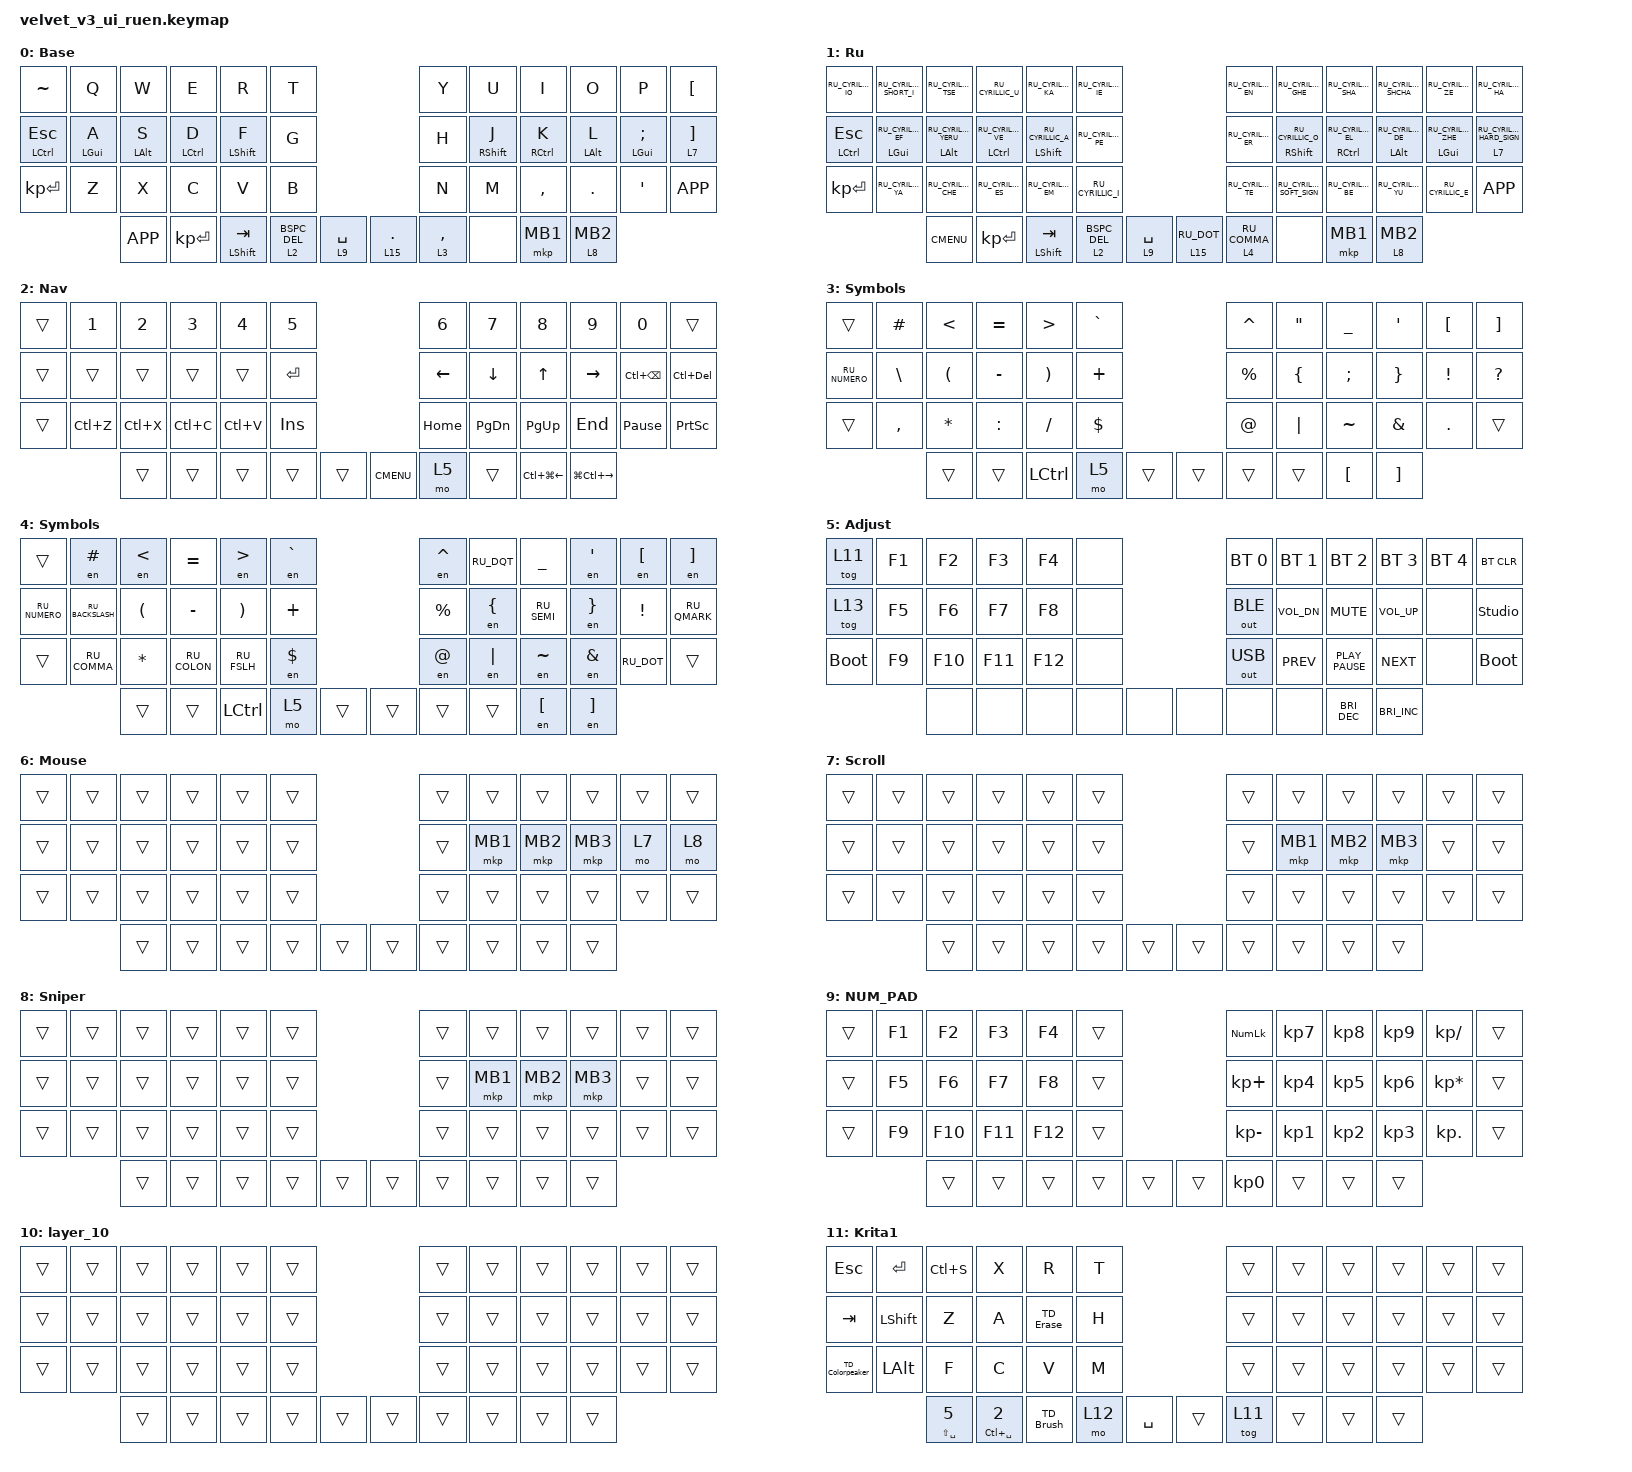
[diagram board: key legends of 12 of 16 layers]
#include "keys_ru.h"
#include <dt-bindings/zmk/input_transform.h>
#include <input/processors.dtsi>
#include <zephyr/dt-bindings/input/input-event-codes.h>
#include <scroll-snap.dtsi>
#include <behaviors.dtsi>
#include <dt-bindings/zmk/bt.h>
#include <dt-bindings/zmk/keys.h>
#include <dt-bindings/zmk/outputs.h>
#include <dt-bindings/zmk/pointing.h>

/ {
    behaviors {
        cap_sen: cap_sen {
            compatible = "zmk,behavior-hold-tap";
            label = "CAP_SEN";
            bindings = <&mo>, <&mkp>;

            #binding-cells = <2>;
            tapping-term-ms = <150>;
            hold-while-undecided;
        };

        hrml: hrml {
            compatible = "zmk,behavior-hold-tap";
            label = "HRML";
            bindings = <&kp>, <&kp>;

            #binding-cells = <2>;
            tapping-term-ms = <175>;
            quick-tap-ms = <175>;
            require-prior-idle-ms = <100>;
            flavor = "balanced";
            hold-trigger-on-release;
            hold-trigger-key-positions = <6 7 8 9 10 11 18 19 20 21 22 23 30 31 32 33 34 35 42 43 44 45 41>;
        };

        hrmr: hrmr {
            compatible = "zmk,behavior-hold-tap";
            label = "HRMR";
            bindings = <&kp>, <&kp>;

            #binding-cells = <2>;
            tapping-term-ms = <175>;
            quick-tap-ms = <175>;
            require-prior-idle-ms = <100>;
            flavor = "balanced";
            hold-trigger-on-release;
            hold-trigger-key-positions = <0 1 2 3 4 5 12 13 14 15 16 17 24 25 26 27 28 29 36 37 38 39 40>;
        };

        TD_Brush: TD_Brush {
            compatible = "zmk,behavior-tap-dance";
            label = "TD_BRUSH";
            #binding-cells = <0>;
            bindings = <&kp B>, <&kp Q>;
        };

        TD_Erase: TD_Erase {
            compatible = "zmk,behavior-tap-dance";
            label = "TD_ERASE";
            #binding-cells = <0>;
            bindings = <&kp E>, <&kp LA(E)>;
        };

        TD_Colorpeaker: TD_Colorpeaker {
            compatible = "zmk,behavior-tap-dance";
            label = "TD_COLORPEAKER";
            #binding-cells = <0>;
            bindings = <&kp LCTRL>, <&kp LA(LCTRL)>;
        };

        MBL_LT: MBL_LT {
            compatible = "zmk,behavior-hold-tap";
            label = "MBL_LT";
            bindings = <&mo>, <&mkp>;

            #binding-cells = <2>;
            hold-trigger-key-positions = <42>;
            tapping-term-ms = <175>;
            require-prior-idle-ms = <100>;
            quick-tap-ms = <150>;
            flavor = "balanced";
            hold-trigger-on-release;
        };

        BSPC_DEL: BSPC_DEL {
            compatible = "zmk,behavior-mod-morph";
            label = "BSPC_DEL";
            bindings = <&kp BSPC>, <&kp DEL>;

            #binding-cells = <0>;
            mods = <(MOD_LSFT|MOD_RSFT)>;
        };

        BCSP_DEL_NAV: BCSP_DEL_NAV {
            compatible = "zmk,behavior-hold-tap";
            label = "BCSP_DEL_NAV";
            bindings = <&mo>, <&BSPC_DEL>;

            #binding-cells = <2>;
            tapping-term-ms = <150>;
            hold-trigger-key-positions = <39>;
            quick-tap-ms = <125>;
            require-prior-idle-ms = <100>;
        };

        mouse_layer: mouse_layer {
            compatible = "zmk,behavior-sticky-key";
            label = "MOUSE_LAYER";
            bindings = <&mo>;
            #binding-cells = <1>;
            release-after-ms = <200>;
        };

        zip_auto_mouse: zip_auto_mouse {
            compatible = "zmk,input-processor-temp-layer";
            #input-processor-cells = <2>;
            require-prior-idle-ms = <800>;
            excluded-positions = <>;
        };
    };

    combos {
        compatible = "zmk,combos";

        cmben {
            bindings = <&layer_en>;
            key-positions = <3 4>;
            layers = <1>;
        };

        cmbru {
            bindings = <&layer_ru>;
            key-positions = <3 4>;
            layers = <0>;
        };

        rusync {
            bindings = <&to 0>;
            key-positions = <8 7>;
            layers = <1>;
        };

        ensycn {
            bindings = <&to 1>;
            key-positions = <8 7>;
            layers = <0>;
        };

        SemiEN {
            bindings = <&kp SEMI>;
            key-positions = <42 41>;
            layers = <0>;
        };

        SemiRU {
            bindings = <&kp RU_SEMI>;
            key-positions = <42 41>;
            layers = <1>;
        };

        MbScrolMode {
            bindings = <&MBL_LT 7 MCLK>;
            key-positions = <44 45>;
            layers = <0 1 2 3 4 5 6 7 8 9>;
        };
    };

    macros {
        to_ru: to_ru {
            compatible = "zmk,behavior-macro";
            #binding-cells = <0>;
            bindings = <&kp LG(SPACE)>;
            label = "TO_RU";
            wait-ms = <0>;
            tap-ms = <0>;
        };

        to_en: to_en {
            compatible = "zmk,behavior-macro";
            #binding-cells = <0>;
            bindings = <&kp LG(SPACE)>;
            label = "TO_EN";
            wait-ms = <0>;
            tap-ms = <0>;
        };

        layer_en: layer_en {
            compatible = "zmk,behavior-macro";
            #binding-cells = <0>;
            bindings = <&to 0 &to_en>;
            label = "LAYER_EN";
            wait-ms = <0>;
            tap-ms = <30>;
        };

        layer_ru: layer_ru {
            compatible = "zmk,behavior-macro";
            #binding-cells = <0>;
            bindings = <&to 1 &to_ru>;
            label = "LAYER_RU";
            tap-ms = <30>;
            wait-ms = <0>;
        };

        en: en {
            compatible = "zmk,behavior-macro-one-param";
            #binding-cells = <1>;
            bindings =
                <&to_en>,
                <&macro_press>,
                <&macro_param_1to1 &kp MACRO_PLACEHOLDER>,
                <&macro_pause_for_release>,
                <&macro_release>,
                <&macro_param_1to1 &kp MACRO_PLACEHOLDER>,
                <&macro_tap>,
                <&to_ru>;

            label = "EN";
            wait-ms = <0>;
            tap-ms = <30>;
        };
    };

    keymap {
        compatible = "zmk,keymap";

        en {
            bindings = <
&kp TILDE      &kp Q             &kp W             &kp E          &kp R               &kp T                                         &kp Y        &kp U                &kp I          &kp O             &kp P                &kp LEFT_BRACKET
&mt LCTRL ESC  &hrml LEFT_GUI A  &hrml LEFT_ALT S  &hrml LCTRL D  &hrml LEFT_SHIFT F  &kp G                                         &kp H        &hrmr RIGHT_SHIFT J  &hrmr RCTRL K  &hrmr LEFT_ALT L  &hrmr LEFT_GUI SEMI  &lt 7 RIGHT_BRACKET
&kp KP_ENTER   &kp Z             &kp X             &kp C          &kp V               &kp B                                         &kp N        &kp M                &kp COMMA      &kp DOT           &kp SQT              &kp K_APP
                                 &kp K_APP         &kp KP_ENTER   &mt LEFT_SHIFT TAB  &BCSP_DEL_NAV 2 0  &lt 9 SPACE    &lt 15 DOT  &lt 3 COMMA  &none                &mkp MB1       &MBL_LT 8 MB2
            >;

            display-name = "Base";
        };

        ru {
            display-name = "Ru";
            bindings = <
&kp RU_CYRILLIC_IO  &kp RU_CYRILLIC_SHORT_I        &kp RU_CYRILLIC_TSE              &kp RU_CYRILLIC_U           &kp RU_CYRILLIC_KA              &kp RU_CYRILLIC_IE                                &kp RU_CYRILLIC_EN  &kp RU_CYRILLIC_GHE         &kp RU_CYRILLIC_SHA         &kp RU_CYRILLIC_SHCHA          &kp RU_CYRILLIC_ZE          &kp RU_CYRILLIC_HA
&mt LCTRL ESC       &hrml LEFT_GUI RU_CYRILLIC_EF  &hrml LEFT_ALT RU_CYRILLIC_YERU  &hrml LCTRL RU_CYRILLIC_VE  &hrml LEFT_SHIFT RU_CYRILLIC_A  &kp RU_CYRILLIC_PE                                &kp RU_CYRILLIC_ER  &hrmr RSHIFT RU_CYRILLIC_O  &hrmr RCTRL RU_CYRILLIC_EL  &hrmr LEFT_ALT RU_CYRILLIC_DE  &hrmr LGUI RU_CYRILLIC_ZHE  &lt 7 RU_CYRILLIC_HARD_SIGN
&kp KP_ENTER        &kp RU_CYRILLIC_YA             &kp RU_CYRILLIC_CHE              &kp RU_CYRILLIC_ES          &kp RU_CYRILLIC_EM              &kp RU_CYRILLIC_I                                 &kp RU_CYRILLIC_TE  &kp RU_CYRILLIC_SOFT_SIGN   &kp RU_CYRILLIC_BE          &kp RU_CYRILLIC_YU             &kp RU_CYRILLIC_E           &kp K_APP
                                                   &kp K_CMENU                      &kp KP_ENTER                &mt LEFT_SHIFT TAB              &BCSP_DEL_NAV 2 0   &lt 9 SPACE    &lt 15 RU_DOT  &lt 4 RU_COMMA      &none                       &mkp MB1                    &MBL_LT 8 MB2
            >;
        };

        nav {
            bindings = <
&trans  &kp N1     &kp N2     &kp N3     &kp N4     &kp N5                          &kp NUMBER_6  &kp NUMBER_7   &kp NUMBER_8      &kp N9             &kp N0             &trans
&trans  &trans     &trans     &trans     &trans     &kp RET                         &kp LEFT      &kp DOWN       &kp UP            &kp RIGHT          &kp LC(BACKSPACE)  &kp LC(DEL)
&trans  &kp LC(Z)  &kp LC(X)  &kp LC(C)  &kp LC(V)  &kp INS                         &kp HOME      &kp PAGE_DOWN  &kp PG_UP         &kp END            &kp PAUSE_BREAK    &kp PRINTSCREEN
                   &trans     &trans     &trans     &trans   &trans    &kp K_CMENU  &mo 5         &trans         &kp LC(LG(LEFT))  &kp LG(LC(RIGHT))
            >;

            display-name = "Nav";
        };

        sym_en {
            bindings = <
&trans         &kp HASH   &kp LT    &kp EQUAL  &kp GT     &kp GRAVE                    &kp CARET  &kp DQT   &kp UNDER  &kp SQT   &kp LBKT  &kp RBKT
&kp RU_NUMERO  &kp BSLH   &kp LPAR  &kp MINUS  &kp RPAR   &kp PLUS                     &kp PRCNT  &kp LBRC  &kp SEMI   &kp RBRC  &kp EXCL  &kp QUESTION
&trans         &kp COMMA  &kp STAR  &kp COLON  &kp FSLH   &kp DLLR                     &kp AT     &kp PIPE  &kp TILDE  &kp AMPS  &kp DOT   &trans
                          &trans    &trans     &kp LCTRL  &mo 5      &trans    &trans  &trans     &trans    &kp LBKT   &kp RBKT
            >;

            display-name = "Symbols";
        };

        sym_ru {
            display-name = "Symbols";
            bindings = <
&trans         &en HASH          &en LT    &kp EQUAL     &en GT       &en GRAVE                    &en CARET  &kp RU_DQT  &kp UNDER    &en SQT   &en LBKT    &en RBKT
&kp RU_NUMERO  &kp RU_BACKSLASH  &kp LPAR  &kp MINUS     &kp RPAR     &kp PLUS                     &kp PRCNT  &en LBRC    &kp RU_SEMI  &en RBRC  &kp EXCL    &kp RU_QMARK
&trans         &kp RU_COMMA      &kp STAR  &kp RU_COLON  &kp RU_FSLH  &en DLLR                     &en AT     &en PIPE    &en TILDE    &en AMPS  &kp RU_DOT  &trans
                                 &trans    &trans        &kp LCTRL    &mo 5      &trans    &trans  &trans     &trans      &en LBKT     &en RBKT
            >;
        };

        adj {
            bindings = <
&tog 11      &kp F1  &kp F2   &kp F3   &kp F4   &none                  &bt BT_SEL 0  &bt BT_SEL 1  &bt BT_SEL 2          &bt BT_SEL 3          &bt BT_SEL 4  &bt BT_CLR
&tog 13      &kp F5  &kp F6   &kp F7   &kp F8   &none                  &out OUT_BLE  &kp C_VOL_DN  &kp K_MUTE            &kp C_VOL_UP          &none         &studio_unlock
&bootloader  &kp F9  &kp F10  &kp F11  &kp F12  &none                  &out OUT_USB  &kp K_PREV    &kp K_PLAY_PAUSE      &kp K_NEXT            &none         &bootloader
                     &none    &none    &none    &none  &none    &none  &none         &none         &kp C_BRIGHTNESS_DEC  &kp C_BRIGHTNESS_INC
            >;

            display-name = "Adjust";
        };

        mouse {
            bindings = <
&trans  &trans  &trans  &trans  &trans  &trans                    &trans  &trans    &trans    &trans    &trans  &trans
&trans  &trans  &trans  &trans  &trans  &trans                    &trans  &mkp MB1  &mkp MB2  &mkp MB3  &mo 7   &mo 8
&trans  &trans  &trans  &trans  &trans  &trans                    &trans  &trans    &trans    &trans    &trans  &trans
                &trans  &trans  &trans  &trans  &trans    &trans  &trans  &trans    &trans    &trans
            >;

            display-name = "Mouse";
        };

        scroll {
            bindings = <
&trans  &trans  &trans  &trans  &trans  &trans                    &trans  &trans    &trans    &trans    &trans  &trans
&trans  &trans  &trans  &trans  &trans  &trans                    &trans  &mkp MB1  &mkp MB2  &mkp MB3  &trans  &trans
&trans  &trans  &trans  &trans  &trans  &trans                    &trans  &trans    &trans    &trans    &trans  &trans
                &trans  &trans  &trans  &trans  &trans    &trans  &trans  &trans    &trans    &trans
            >;

            display-name = "Scroll";
        };

        sniper {
            bindings = <
&trans  &trans  &trans  &trans  &trans  &trans                    &trans  &trans    &trans    &trans    &trans  &trans
&trans  &trans  &trans  &trans  &trans  &trans                    &trans  &mkp MB1  &mkp MB2  &mkp MB3  &trans  &trans
&trans  &trans  &trans  &trans  &trans  &trans                    &trans  &trans    &trans    &trans    &trans  &trans
                &trans  &trans  &trans  &trans  &trans    &trans  &trans  &trans    &trans    &trans
            >;

            display-name = "Sniper";
        };

        NUM_PAD {
            bindings = <
&trans  &kp F1  &kp F2   &kp F3   &kp F4   &trans                    &kp KP_NUMLOCK   &kp KP_N7  &kp KP_N8  &kp KP_N9  &kp KP_SLASH     &trans
&trans  &kp F5  &kp F6   &kp F7   &kp F8   &trans                    &kp KP_PLUS      &kp KP_N4  &kp KP_N5  &kp KP_N6  &kp KP_MULTIPLY  &trans
&trans  &kp F9  &kp F10  &kp F11  &kp F12  &trans                    &kp KP_MINUS     &kp KP_N1  &kp KP_N2  &kp KP_N3  &kp KP_DOT       &trans
                &trans   &trans   &trans   &trans  &trans    &trans  &kp KP_NUMBER_0  &trans     &trans     &trans
            >;
        };

        layer_10 {
            bindings = <
&trans  &trans  &trans  &trans  &trans  &trans                    &trans  &trans  &trans  &trans  &trans  &trans
&trans  &trans  &trans  &trans  &trans  &trans                    &trans  &trans  &trans  &trans  &trans  &trans
&trans  &trans  &trans  &trans  &trans  &trans                    &trans  &trans  &trans  &trans  &trans  &trans
                &trans  &trans  &trans  &trans  &trans    &trans  &trans  &trans  &trans  &trans
            >;
        };

        Krita1 {
            bindings = <
&kp ESC          &kp RET    &kp LC(S)         &kp X                   &kp R      &kp T                        &trans   &trans  &trans  &trans  &trans  &trans
&kp TAB          &kp LSHFT  &kp Z             &kp A                   &TD_Erase  &kp H                        &trans   &trans  &trans  &trans  &trans  &trans
&TD_Colorpeaker  &kp LALT   &kp F             &kp C                   &kp V      &kp M                        &trans   &trans  &trans  &trans  &trans  &trans
                            &mt LS(SPACE) N5  &mt LC(SPACE) NUMBER_2  &TD_Brush  &mo 12  &kp SPACE    &trans  &tog 11  &trans  &trans  &trans
            >;
        };

        Krita2 {
            bindings = <
&trans         &kp LC(G)           &kp LC(E)   &kp LC(T)      &kp INS    &kp LC(INS)                    &trans  &trans  &trans  &trans  &trans  &trans
&kp LC(LS(I))  &kp LS(LC(A))       &kp LC(A)   &kp LC(PG_UP)  &kp LA(H)  &kp LA(INS)                    &trans  &trans  &trans  &trans  &trans  &trans
&trans         &kp LC(LS(DELETE))  &kp DELETE  &kp LC(PG_DN)  &kp LS(H)  &kp LC(N)                      &trans  &trans  &trans  &trans  &trans  &trans
                                   &kp LC(C)   &kp LC(V)      &trans     &trans       &trans    &trans  &trans  &trans  &trans  &trans
            >;
        };

        GameBase {
            bindings = <
&kp ESC    &kp GRAVE       &kp Q  &kp W  &kp E   &kp R                         &trans     &trans    &kp UP    &trans     &trans  &trans
&kp RCTRL  &kp LEFT_SHIFT  &kp A  &kp S  &kp D   &kp F                         &trans     &kp LEFT  &kp DOWN  &kp RIGHT  &trans  &trans
&kp LALT   &kp Z           &kp X  &kp C  &kp V   &kp B                         &trans     &trans    &trans    &trans     &trans  &trans
                           &kp I  &kp M  &trans  &kp SPACE  &mo 14    &tog 13  &kp SPACE  &trans    &trans    &trans
            >;
        };

        GameFunc {
            bindings = <
&trans  &kp N1  &kp N2   &kp N3   &kp N4  &kp N5                    &trans  &trans  &trans  &trans  &trans  &trans
&trans  &kp N6  &kp N7   &kp N8   &kp N9  &kp N0                    &trans  &trans  &trans  &trans  &trans  &trans
&trans  &kp G   &kp J    &kp I    &kp M   &kp T                     &trans  &trans  &trans  &trans  &trans  &trans
                &kp ESC  &kp RET  &trans  &trans  &trans    &trans  &trans  &trans  &trans  &trans
            >;
        };

        Func1C {
            bindings = <
&trans  &trans  &trans            &trans                &trans  &trans                    &trans  &trans  &trans  &trans  &trans  &trans
&trans  &trans  &trans            &trans                &trans  &trans                    &trans  &trans  &trans  &trans  &trans  &trans
&trans  &trans  &trans            &trans                &trans  &trans                    &trans  &trans  &trans  &trans  &trans  &trans
                &kp LC(KP_SLASH)  &kp LS(LC(KP_SLASH))  &trans  &trans  &trans    &trans  &trans  &trans  &trans  &trans
            >;
        };
    };
};

&trackball { cpi = <1000>; };

&trackball_listener {
    input-processors = <&zip_xy_scaler 9 20>;

    scroller {
        layers = <7>;
        input-processors =
            <&zip_xy_transform INPUT_TRANSFORM_Y_INVERT>,
            <&zip_xy_scaler 1 32>,
            <&zip_xy_to_scroll_mapper &zip_scroll_snap>;
    };

    sniper {
        layers = <8>;
        input-processors = <&zip_xy_scaler 1 4>;
    };
};
